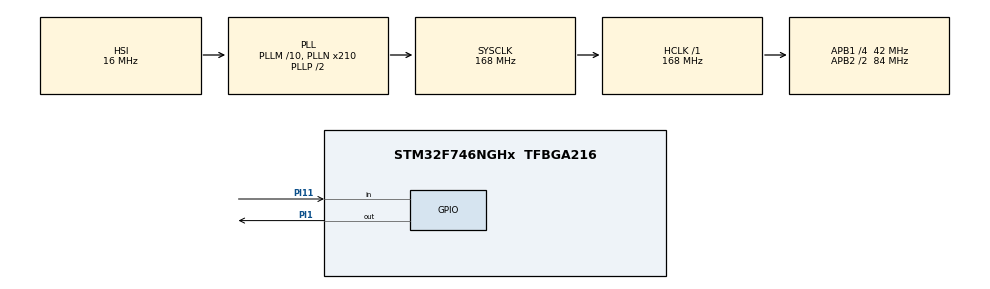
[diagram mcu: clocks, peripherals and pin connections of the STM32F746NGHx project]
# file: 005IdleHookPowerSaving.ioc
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Mcu.Family=STM32F7
Mcu.Name=STM32F746NGHx
Mcu.Package=TFBGA216
NVIC.PriorityGroup=NVIC_PRIORITYGROUP_4
PI1.Signal=GPIO_Output
PI11.Signal=GPIO_Input
ProjectManager.HeapSize=0x200
ProjectManager.StackSize=0x400
ProjectManager.TargetToolchain=STM32CubeIDE
RCC.AHBFreq_Value=168000000
RCC.APB1CLKDivider=RCC_HCLK_DIV4
RCC.APB1Freq_Value=42000000
RCC.APB1TimFreq_Value=84000000
RCC.APB2CLKDivider=RCC_HCLK_DIV2
RCC.APB2Freq_Value=84000000
RCC.APB2TimFreq_Value=168000000
RCC.CortexFreq_Value=168000000
RCC.HCLKFreq_Value=168000000
RCC.HSE_VALUE=25000000
RCC.HSI_VALUE=16000000
RCC.LSE_VALUE=32768
RCC.PLLM=10
RCC.PLLN=210
RCC.PLLSourceVirtual=RCC_PLLSOURCE_HSI
RCC.SYSCLKFreq_VALUE=168000000
RCC.SYSCLKSource=RCC_SYSCLKSOURCE_PLLCLK
RCC.USBFreq_Value=168000000
RCC.VCOOutputFreq_Value=336000000
board=STM32F746G-DISCO

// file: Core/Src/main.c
/* USER CODE BEGIN Header */
/**
  ******************************************************************************
  * @file           : main.c
  * @brief          : Main program body
  ******************************************************************************
  * @attention
  *
  * Copyright (c) 2025 STMicroelectronics.
  * All rights reserved.
  *
  * This software is licensed under terms that can be found in the LICENSE file
  * in the root directory of this software component.
  * If no LICENSE file comes with this software, it is provided AS-IS.
  *
  ******************************************************************************
  */
/* USER CODE END Header */
#include "main.h"

/* USER CODE BEGIN Includes */
#include <stdio.h>
#include "FreeRTOS.h"
#include "task.h"
/* USER CODE END Includes */

void SystemClock_Config(void);
static void MX_GPIO_Init(void);
/* USER CODE BEGIN PFP */
static void led_handler(void *parameters);
/* USER CODE END PFP */

/* USER CODE BEGIN 0 */
void vAssertCalled(uint32_t ulLine, const char *pcFile)
{
    __disable_irq();
    while(1);
}
/* USER CODE END 0 */

int main(void)
{

  /* USER CODE BEGIN 1 */
	TaskHandle_t led_handle;
	BaseType_t status;
  /* USER CODE END 1 */

  /* MCU Configuration--------------------------------------------------------*/

  /* Reset of all peripherals, Initializes the Flash interface and the Systick. */
  HAL_Init();

  /* Configure the system clock */
  SystemClock_Config();

  /* Initialize all configured peripherals */
  MX_GPIO_Init();
  /* USER CODE BEGIN 2 */

  status = xTaskCreate(led_handler, "Led task", 200, NULL, 2, &led_handle);
  configASSERT(status == pdPASS);

  vTaskStartScheduler();
  /* USER CODE END 2 */

  /* Infinite loop */
  while (1)
  {

  }
}

void SystemClock_Config(void)
{
  RCC_OscInitTypeDef RCC_OscInitStruct = {0};
  RCC_ClkInitTypeDef RCC_ClkInitStruct = {0};

  /** Configure the main internal regulator output voltage
  */
  __HAL_RCC_PWR_CLK_ENABLE();
  __HAL_PWR_VOLTAGESCALING_CONFIG(PWR_REGULATOR_VOLTAGE_SCALE2);

  /** Initializes the RCC Oscillators according to the specified parameters
  * in the RCC_OscInitTypeDef structure.
  */
  RCC_OscInitStruct.OscillatorType = RCC_OSCILLATORTYPE_HSI;
  RCC_OscInitStruct.HSIState = RCC_HSI_ON;
  RCC_OscInitStruct.HSICalibrationValue = RCC_HSICALIBRATION_DEFAULT;
  RCC_OscInitStruct.PLL.PLLState = RCC_PLL_ON;
  RCC_OscInitStruct.PLL.PLLSource = RCC_PLLSOURCE_HSI;
  RCC_OscInitStruct.PLL.PLLM = 10;
  RCC_OscInitStruct.PLL.PLLN = 210;
  RCC_OscInitStruct.PLL.PLLP = RCC_PLLP_DIV2;
  RCC_OscInitStruct.PLL.PLLQ = 2;
  if (HAL_RCC_OscConfig(&RCC_OscInitStruct) != HAL_OK)
  {
    Error_Handler();
  }

  /** Initializes the CPU, AHB and APB buses clocks
  */
  RCC_ClkInitStruct.ClockType = RCC_CLOCKTYPE_HCLK|RCC_CLOCKTYPE_SYSCLK
                              |RCC_CLOCKTYPE_PCLK1|RCC_CLOCKTYPE_PCLK2;
  RCC_ClkInitStruct.SYSCLKSource = RCC_SYSCLKSOURCE_PLLCLK;
  RCC_ClkInitStruct.AHBCLKDivider = RCC_SYSCLK_DIV1;
  RCC_ClkInitStruct.APB1CLKDivider = RCC_HCLK_DIV4;
  RCC_ClkInitStruct.APB2CLKDivider = RCC_HCLK_DIV2;

  if (HAL_RCC_ClockConfig(&RCC_ClkInitStruct, FLASH_LATENCY_5) != HAL_OK)
  {
    Error_Handler();
  }
}

static void MX_GPIO_Init(void)
{
  GPIO_InitTypeDef GPIO_InitStruct = {0};

  /* GPIO Ports Clock Enable */
  __HAL_RCC_GPIOI_CLK_ENABLE();

  /*Configure GPIO pin Output Level */
  HAL_GPIO_WritePin(GPIOI, GPIO_PIN_1, GPIO_PIN_RESET);

  /*Configure GPIO pin : PI1 */
  GPIO_InitStruct.Pin = GPIO_PIN_1;
  GPIO_InitStruct.Mode = GPIO_MODE_OUTPUT_PP;
  GPIO_InitStruct.Pull = GPIO_NOPULL;
  GPIO_InitStruct.Speed = GPIO_SPEED_FREQ_LOW;
  HAL_GPIO_Init(GPIOI, &GPIO_InitStruct);

  /*Configure GPIO pin : PI11 */
  GPIO_InitStruct.Pin = GPIO_PIN_11;
  GPIO_InitStruct.Mode = GPIO_MODE_INPUT;
  GPIO_InitStruct.Pull = GPIO_NOPULL;
  HAL_GPIO_Init(GPIOI, &GPIO_InitStruct);

}

/* USER CODE BEGIN 4 */
static void led_handler(void *parameters)
{
	while(1)
	{

			HAL_GPIO_TogglePin(GPIOI, GPIO_PIN_1);

			vTaskDelay(pdMS_TO_TICKS(1000));

	}
}

void vApplicationIdleHook(void)
{
	HAL_PWR_EnterSLEEPMode(PWR_MAINREGULATOR_ON, PWR_SLEEPENTRY_WFI);

}
/* USER CODE END 4 */

void Error_Handler(void)
{
  __disable_irq();
  while (1)
  {
  }
}
